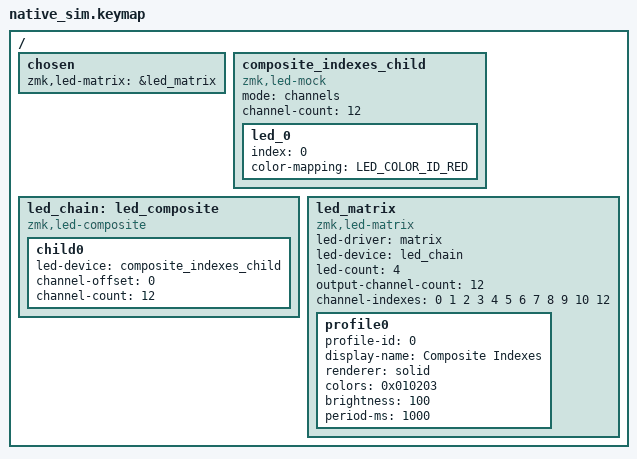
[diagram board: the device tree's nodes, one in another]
#include "../behavior_keymap.dtsi"

/ {
    chosen {
        zmk,led-matrix = &led_matrix;
    };

    composite_indexes_child: composite_indexes_child {
        compatible = "zmk,led-mock";
        mode = "channels";
        channel-count = <12>;

        led_0 {
            index = <0>;
            color-mapping = <LED_COLOR_ID_RED>;
        };
    };

    led_chain: led_composite {
        compatible = "zmk,led-composite";

        child0 {
            led-device = <&composite_indexes_child>;
            channel-offset = <0>;
            channel-count = <12>;
        };
    };

    led_matrix: led_matrix {
        compatible = "zmk,led-matrix";
        led-driver = "matrix";
        led-device = <&led_chain>;
        led-count = <4>;
        output-channel-count = <12>;
        channel-indexes = <
            0 1 2
            3 4 5
            6 7 8
            9 10 12
        >;

        profile0 {
            profile-id = <0>;
            display-name = "Composite Indexes";
            renderer = "solid";
            colors = <0x010203>;
            brightness = <100>;
            period-ms = <1000>;
        };
    };
};
